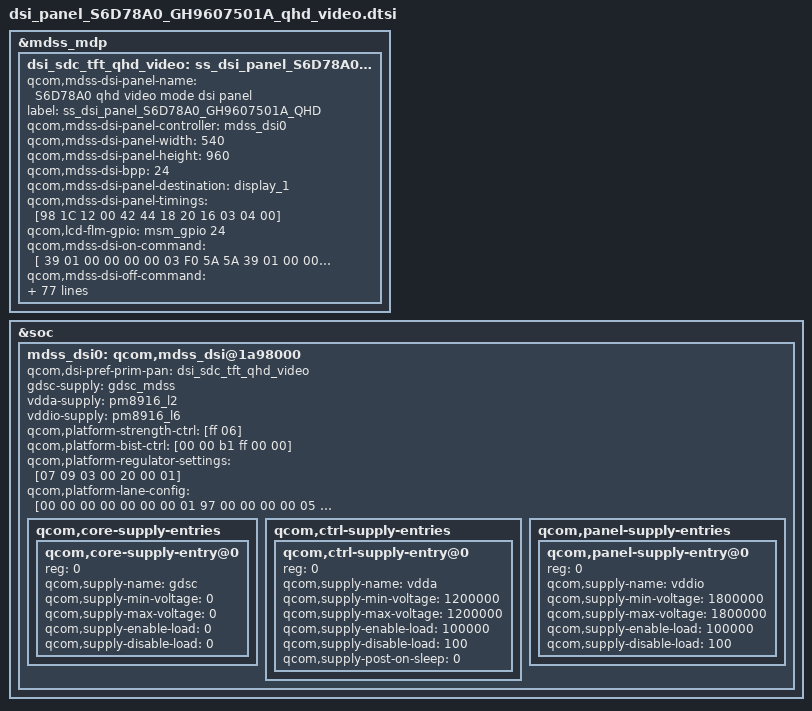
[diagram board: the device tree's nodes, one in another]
/* Copyright (c) 2013-14, Samsung Electronics Corporation. All rights reserved.
 *
 * This program is free software; you can redistribute it and/or modify
 * it under the terms of the GNU General Public License version 2 and
 * only version 2 as published by the Free Software Foundation.
 *
 * This program is distributed in the hope that it will be useful,
 * but WITHOUT ANY WARRANTY; without even the implied warranty of
 * MERCHANTABILITY or FITNESS FOR A PARTICULAR PURPOSE.  See the
 * GNU General Public License for more details.
 */

/*---------------------------------------------------------------------------
 * This file is autogenerated file using gcdb parser. Please do not edit it.
 * Update input XML file to add a new entry or update variable in this file
 * VERSION = "1.0"
 *---------------------------------------------------------------------------

 */
&mdss_mdp {
	dsi_sdc_tft_qhd_video: ss_dsi_panel_S6D78A0_GH9607501A_QHD {
		qcom,mdss-dsi-panel-name = "S6D78A0 qhd video mode dsi panel";
		label = "ss_dsi_panel_S6D78A0_GH9607501A_QHD";
		qcom,mdss-dsi-panel-controller = <&mdss_dsi0>;
		qcom,mdss-dsi-panel-width = <540>;
		qcom,mdss-dsi-panel-height = <960>;
		qcom,mdss-dsi-bpp = <24>;
		qcom,mdss-dsi-panel-destination = "display_1";
		qcom,mdss-dsi-panel-timings = [98 1C 12 00 42 44 18 20 16 03 04 00];
		qcom,lcd-flm-gpio = <&msm_gpio 24 0>;
		qcom,mdss-dsi-on-command = [
			/* Initializing Sequennce(1) */
			39 01 00 00 00 00 03 F0 5A 5A
			39 01 00 00 00 00 03 F1 5A 5A
			39 01 00 00 00 00 03 FC A5 A5
			/* Initializing Sequennce(2) */
			39 01 00 00 00 00 02 B1 93	// Internal CLK
			39 01 00 00 00 00 02 B5 10	// Panel Protection
			39 01 00 00 00 00 12 F4 01 10 32 00 24 26 28 27 27 27 B7 2B 2C 65 6A 34 20	// 18 ea, Internal Power Sequence
			39 01 00 00 00 00 15 EF 01 01 81 22 83 04 00 00 00 00 28 81 00 21 21 03 03 40 00 10	// 21 ea, GOA Timing
			39 01 00 00 00 00 09 F2 19 04 08 08 08 14 14 00	// Internal Porch
			39 01 00 00 00 00 07 F6 93 23 15 07 07 0C	// Source Control
			39 01 00 00 00 00 07 E1 01 FF 01 1B 20 17	// MIPI Abnormal Detect
			39 01 00 00 00 00 04 E2 ED C7 23	// MIPI Auto Recover
			39 01 00 00 00 00 27 F7 01 01 0A 0B 05 1B 1A 01 01 01 01 01 01 01 01 01 01 01 01 01 01 08 09 04 1B 1A 01 01 01 01 01 01 01 01 01 01 01 01	// 39, GOA Output
			39 01 00 00 00 00 02 36 10	// Memory Data Access Control
			39 01 00 00 00 00 28 FA 00 19 21 1E 14 0B 10 0E 09 0B 00 00 0A 00 1D 21 1E 14 0B 10 0E 09 0B 00 00 0A 00 1C 21 1E 14 0B 10 0E 09 0B 00 00 0A // 40, Positive Gamma Control
			39 01 00 00 00 00 28 FB 07 2D 22 24 18 0E 11 0C 05 05 00 00 0A 00 29 22 24 18 0E 11 0C 05 05 00 00 0A 07 2A 22 24 18 0E 11 0C 05 05 00 00 0A //Negative Gamma Control
			05 01 00 00 14 00 02 29 00
			39 01 00 00 00 00 03 F0 A5 A5
			39 01 00 00 00 00 03 F1 A5 A5
			39 01 00 00 00 00 03 FC 5A 5A
		];
		qcom,mdss-dsi-off-command = [
			/* < Deep Sleep In Sequence > */
			39 01 00 00 28 00 02 28 00
			39 01 00 00 64 00 02 10 00
		];
		samsung,display_on_tx_cmds_revA = [05 01 00 00 78 00 02 11 00];
		qcom,mdss-dsi-panel-type = "dsi_video_mode";
		qcom,lcd-esd-det-gpio = <&msm_gpio 69 0>;
		qcom,mdss-dsi-panel-framerate = <60>;
		qcom,mdss-dsi-virtual-channel-id = <0>;
		qcom,mdss-dsi-stream = <0>;
		qcom,cont-splash-enabled;

		qcom,mdss-dsi-h-front-porch = <40>;
		qcom,mdss-dsi-h-back-porch = <40>;
		qcom,mdss-dsi-h-pulse-width = <38>;
		qcom,mdss-dsi-h-sync-skew = <0>;
		qcom,mdss-dsi-v-back-porch = <6>;
		qcom,mdss-dsi-v-front-porch = <8>;
		qcom,mdss-dsi-v-pulse-width = <2>;
		qcom,mdss-dsi-h-left-border = <0>;
		qcom,mdss-dsi-h-right-border = <0>;
		qcom,mdss-dsi-v-top-border = <0>;
		qcom,mdss-dsi-v-bottom-border = <0>;
		qcom,mdss-dsi-color-order = <0>;
		qcom,mdss-dsi-underflow-color = <0xff>;
		qcom,mdss-dsi-border-color = <0>;
		/* Overridden in board device tree as this functionality changes between hardware revision */
		qcom,mdss-dsi-lane-0-state;
		qcom,mdss-dsi-on-command-state = "dsi_lp_mode";
		qcom,mdss-dsi-off-command-state = "dsi_hs_mode";
		qcom,mdss-dsi-lane-1-state;
		qcom,mdss-dsi-h-sync-pulse = <0>;
		qcom,mdss-dsi-traffic-mode = "non_burst_sync_pulse";
		qcom,mdss-dsi-bllp-eof-power-mode;
		qcom,mdss-dsi-bllp-power-mode;
		qcom,mdss-dsi-lane-map = <0>;
		qcom,mdss-dsi-t-clk-post = <0x04>;
		qcom,mdss-dsi-t-clk-pre = <0x18>;
		qcom,mdss-dsi-bl-min-level = <1>;
		qcom,mdss-dsi-bl-max-level = <255>;
		qcom,mdss-dsi-dma-trigger = "trigger_sw";
		qcom,mdss-dsi-mdp-trigger = "none";
		qcom,mdss-dsi-bl-pmic-control-type = "bl_ctrl_ss_pwm";
		qcom,mdss-dsi-reset-sequence = <1 10>, <0 5>, <1 30>;
		qcom,mdss-pan-physical-width-dimension = <62>; /* <Width> real size of panel in mm */
		qcom,mdss-pan-physical-height-dimension = <110>; /*<Height> real size of panel in mm */
		qcom,mdss-dsi-lp11-init;
		qcom,mdss-force-clk-lane-hs;
		qcom,mdss-dsi-force-clk-lane-hs;
		qcom,mdss-dsi-init-delay-us = <100>;
		qcom,mdss-power-off-delay-us = <12000>;
/*
 * ************************************************************************************************************************************
 *
 *
 *			Below  parameters are samsung dependent thigs
 *
 *
 * ************************************************************************************************************************************
 */
		samsung,tft-common-support;
		samsung,panel-vendor = "INH";
		samsung,packet_size_tx_cmds_revA = [
			37 01 00 00 00 00 02 07 00
		];

		samsung,level1_key_enable_tx_cmds_revA = [
			29 01 00 00 00 00 03 F0 5A 5A
		];
		samsung,level1_key_disable_tx_cmds_revA = [
			29 01 00 00 00 00 03 F0 A5 A5
		];
		samsung,level2_key_enable_tx_cmds_revA = [
			29 01 00 00 00 00 03 FC 5A 5A
		];
		samsung,level2_key_disable_tx_cmds_revA = [
			29 01 00 00 00 00 03 FC A5 A5
		];

		/*
		 * First parameters can be changed
		 * by function of samsung_nv_read()
		 * because of that means offset of
		 * read position
		 */
		samsung,reg_read_pos_tx_cmds_revA = [
			15 01 00 00 00 00 02 B0 00
		];
		samsung,manufacture_id0_rx_cmds_revA = [06 01 00 00 00 00 01 da 03 00];
		samsung,manufacture_id1_rx_cmds_revA = [06 01 00 00 00 00 01 db 03 00];
		samsung,manufacture_id2_rx_cmds_revA = [06 01 00 00 00 00 01 dc 03 00];
		/*
		 * Command sets for CABC control
		 */
		samsung,tft_pwm_tx_cmds_revA=[
			39 01 00 00 00 00 02 51 FF/*First command should be PWM duty change command*/
		];
		samsung,cabc_on_tx_cmds_revA = [
			39 01 00 00 00 00 02 55 01
		];
		samsung,cabc_off_tx_cmds_revA = [
			39 01 00 00 00 00 02 55 00
		];
		/*
		* ************************************************************************************************************************
		* Scaled level to index mappings
		* ************************************************************************************************************************
		*/
		samsung,scaled_level_map_table_revA = <
		/* <idx>	    <from>       <till>     <scaled_level> */
			0		0		0		0
			1		1		7		32
			2		8		13		31
			3		14		19		30
			4		20		25		29
			5		26		31		28
			6		32		37		27
			7		38		43		26
			8		44		49		25
			9		50		56		24
			10		57		64		23
			11		65		72		22
			12		73		80		21
			13		81		88		20
			14		89		96		19
			15		97		105		18
			16		106		114		17
			17		115		123		16
			18		124		133		15
			19		134		143		14
			20		144		153		13
			21		154		163		12
			22		164		173		11
			23		174		183		10
			24		184		193		9
			25		194		203		8
			26		204		213		7
			27		214		223		6
			28		224		233		5
			29		234		243		4
			30		244		255		3
			>;
	};
};
&soc {
	mdss_dsi0: qcom,mdss_dsi@1a98000 {
		qcom,dsi-pref-prim-pan = <&dsi_sdc_tft_qhd_video>;
		gdsc-supply = <&gdsc_mdss>;
		vdda-supply = <&pm8916_l2>;
		vddio-supply = <&pm8916_l6>;
		qcom,platform-strength-ctrl = [ff 06];
		qcom,platform-bist-ctrl = [00 00 b1 ff 00 00];
		qcom,platform-regulator-settings = [07 09 03 00 20 00 01];
		qcom,platform-lane-config = [00 00 00 00 00 00 00 01 97
			00 00 00 00 05 00 00 01 97
			00 00 00 00 0a 00 00 01 97
			00 00 00 00 0f 00 00 01 97
			00 c0 00 00 00 00 00 01 bb];
		qcom,core-supply-entries {
			#address-cells = <1>;
			#size-cells = <0>;

			qcom,core-supply-entry@0 {
				reg = <0>;
				qcom,supply-name = "gdsc";
				qcom,supply-min-voltage = <0>;
				qcom,supply-max-voltage = <0>;
				qcom,supply-enable-load = <0>;
				qcom,supply-disable-load = <0>;
			};
		};
		qcom,ctrl-supply-entries {
			#address-cells = <1>;
			#size-cells = <0>;

			qcom,ctrl-supply-entry@0 {
				reg = <0>;
				qcom,supply-name = "vdda";
				qcom,supply-min-voltage = <1200000>;
				qcom,supply-max-voltage = <1200000>;
				qcom,supply-enable-load = <100000>;
				qcom,supply-disable-load = <100>;
				qcom,supply-post-on-sleep = <0>;
			};
		};
		qcom,panel-supply-entries {
			#address-cells = <1>;
			#size-cells = <0>;

			qcom,panel-supply-entry@0 {
				reg = <0>;
				qcom,supply-name = "vddio";
				qcom,supply-min-voltage = <1800000>;
				qcom,supply-max-voltage = <1800000>;
				qcom,supply-enable-load = <100000>;
				qcom,supply-disable-load = <100>;
			};
		};
	};
};

